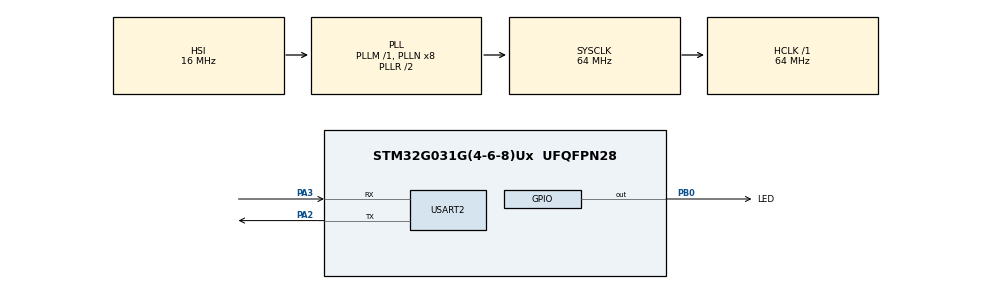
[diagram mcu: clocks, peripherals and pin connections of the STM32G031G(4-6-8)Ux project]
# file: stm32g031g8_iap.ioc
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Mcu.Family=STM32G0
Mcu.Name=STM32G031G(4-6-8)Ux
Mcu.Package=UFQFPN28
PA2.Mode=Asynchronous
PA2.Signal=USART2_TX
PA3.Mode=Asynchronous
PA3.Signal=USART2_RX
PB0.GPIO_Label=LED
PB0.Signal=GPIO_Output
ProjectManager.HeapSize=0x200
ProjectManager.StackSize=0x400
ProjectManager.TargetToolchain=MDK-ARM V5.27
RCC.ADCFreq_Value=64000000
RCC.AHBFreq_Value=64000000
RCC.CortexFreq_Value=64000000
RCC.EXTERNAL_CLOCK_VALUE=12288000
RCC.HCLKFreq_Value=64000000
RCC.HSE_VALUE=8000000
RCC.HSI_VALUE=16000000
RCC.LSE_VALUE=32768
RCC.SYSCLKFreq_VALUE=64000000
RCC.SYSCLKSource=RCC_SYSCLKSOURCE_PLLCLK
RCC.VCOOutputFreq_Value=128000000
USART2.VirtualMode-Asynchronous=VM_ASYNC
VP_IWDG_VS_IWDG.Mode=IWDG_Activate
board=custom

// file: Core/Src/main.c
/**
 * @file main.c
 * @brief STM32G031G8 Bootloader iap测试程序
 * @version 1.0
 * @author Alan
 * @date 2024年8月02日
 */

#include "main.h"
#include "iwdg.h"
#include "usart.h"
#include "gpio.h"
#include "string.h"
#include "menu.h"

config_data_t Read_Config = {0};

void SystemClock_Config(void);
void Flash_OB_Handle(void);

void SystemClock_Config(void);

int main(void)
{
    HAL_Init();
    SystemClock_Config();

    MX_GPIO_Init();

    MX_USART2_UART_Init();

    Flash_OB_Handle(); // 把nBOOT_sel的√拉低
    Serial_PutString((uint8_t *)"iap init ok\n");

    STMFLASH_Read(CONFIG_START_ADDRESS, (uint8_t *)&Read_Config, sizeof(Read_Config));
    // 1.检查标志位
    if (Read_Config.updata_flg == UPDATA)
    {
        // 2.检查产品名称
        if (strcmp(Read_Config.device_name, DEVICE_NAME) == 0)
        {
            // 3.检查硬件版本
            if (Read_Config.HW_vision == HW_VERSION)
            {
               ReadyToUpdate();
            }
            else if (Read_Config.HW_vision != HW_VERSION)
            {
                Serial_PutString((uint8_t *)"hardware version err!\n");
            }
        }
        else if (Read_Config.device_name != DEVICE_NAME)
        {
            //Serial_PutString((uint8_t*)"not this device!\n");
            goto Application;
        }
    }
    else
    {
        JumpToApplication_Funtion();
    }

Application:
    JumpToApplication_Funtion();

    while (1)
    {
    }
}

void SystemClock_Config(void)
{
    RCC_OscInitTypeDef RCC_OscInitStruct = {0};
    RCC_ClkInitTypeDef RCC_ClkInitStruct = {0};

    /** Configure the main internal regulator output voltage
     */
    HAL_PWREx_ControlVoltageScaling(PWR_REGULATOR_VOLTAGE_SCALE1);

    /** Initializes the RCC Oscillators according to the specified parameters
     * in the RCC_OscInitTypeDef structure.
     */
    RCC_OscInitStruct.OscillatorType = RCC_OSCILLATORTYPE_HSI | RCC_OSCILLATORTYPE_LSI;
    RCC_OscInitStruct.HSIState = RCC_HSI_ON;
    RCC_OscInitStruct.HSIDiv = RCC_HSI_DIV1;
    RCC_OscInitStruct.HSICalibrationValue = RCC_HSICALIBRATION_DEFAULT;
    RCC_OscInitStruct.LSIState = RCC_LSI_ON;
    RCC_OscInitStruct.PLL.PLLState = RCC_PLL_ON;
    RCC_OscInitStruct.PLL.PLLSource = RCC_PLLSOURCE_HSI;
    RCC_OscInitStruct.PLL.PLLM = RCC_PLLM_DIV1;
    RCC_OscInitStruct.PLL.PLLN = 8;
    RCC_OscInitStruct.PLL.PLLP = RCC_PLLP_DIV2;
    RCC_OscInitStruct.PLL.PLLQ = RCC_PLLQ_DIV2;
    RCC_OscInitStruct.PLL.PLLR = RCC_PLLR_DIV2;
    if (HAL_RCC_OscConfig(&RCC_OscInitStruct) != HAL_OK)
    {
        Error_Handler();
    }

    /** Initializes the CPU, AHB and APB buses clocks
     */
    RCC_ClkInitStruct.ClockType = RCC_CLOCKTYPE_HCLK | RCC_CLOCKTYPE_SYSCLK | RCC_CLOCKTYPE_PCLK1;
    RCC_ClkInitStruct.SYSCLKSource = RCC_SYSCLKSOURCE_PLLCLK;
    RCC_ClkInitStruct.AHBCLKDivider = RCC_SYSCLK_DIV1;
    RCC_ClkInitStruct.APB1CLKDivider = RCC_HCLK_DIV1;

    if (HAL_RCC_ClockConfig(&RCC_ClkInitStruct, FLASH_LATENCY_2) != HAL_OK)
    {
        Error_Handler();
    }
}

/* USER CODE BEGIN 4 */
void Flash_OB_Handle(void)
{
    FLASH_OBProgramInitTypeDef optionsbytesstruct;
    _Bool UPDATE = 0;
    HAL_FLASHEx_OBGetConfig(&optionsbytesstruct);
    uint32_t userconfig = optionsbytesstruct.USERConfig;

    /*把nBOOT_SEL 不勾选，要按住boot0 ->3.3v上电*/
    if ((userconfig & FLASH_OPTR_nBOOT_SEL_Msk) != OB_BOOT0_FROM_PIN)
    {
        userconfig &= ~FLASH_OPTR_nBOOT_SEL_Msk;
        userconfig |= OB_BOOT0_FROM_PIN;
        UPDATE = 1;
    }

    if (UPDATE)
    {
        optionsbytesstruct.USERConfig = userconfig;
        HAL_FLASH_Unlock();
        HAL_FLASH_OB_Unlock();
        HAL_FLASHEx_OBProgram(&optionsbytesstruct);
        HAL_FLASH_OB_Launch();
        HAL_FLASH_OB_Lock();
        HAL_FLASH_Lock();
    }
}
/* USER CODE END 4 */

void Error_Handler(void)
{
    __disable_irq();
    while (1)
    {
    }
}
